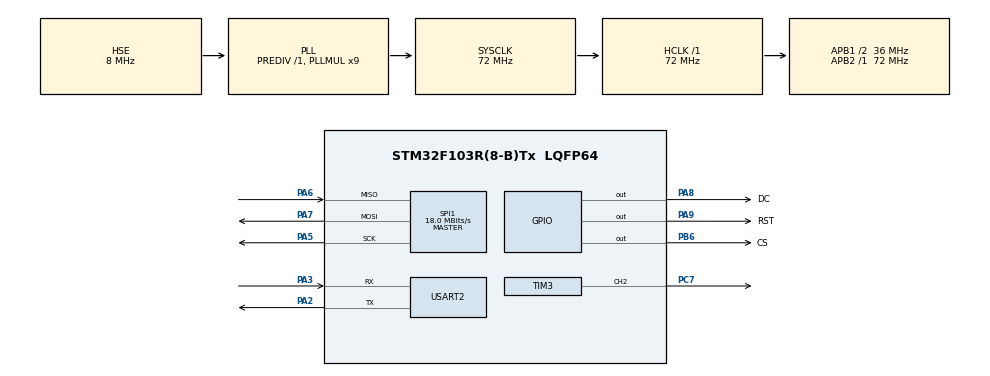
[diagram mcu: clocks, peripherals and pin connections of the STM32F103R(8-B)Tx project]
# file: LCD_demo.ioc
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Mcu.Family=STM32F1
Mcu.Name=STM32F103R(8-B)Tx
Mcu.Package=LQFP64
NVIC.PriorityGroup=NVIC_PRIORITYGROUP_4
PA13.Mode=Serial_Wire
PA13.Signal=SYS_JTMS-SWDIO
PA14.Mode=Serial_Wire
PA14.Signal=SYS_JTCK-SWCLK
PA2.Mode=Asynchronous
PA2.Signal=USART2_TX
PA3.Mode=Asynchronous
PA3.Signal=USART2_RX
PA5.Mode=Full_Duplex_Master
PA5.Signal=SPI1_SCK
PA6.Mode=Full_Duplex_Master
PA6.Signal=SPI1_MISO
PA7.Mode=Full_Duplex_Master
PA7.Signal=SPI1_MOSI
PA8.GPIO_Label=DC
PA8.PinState=GPIO_PIN_SET
PA8.Signal=GPIO_Output
PA9.GPIO_Label=RST
PA9.PinState=GPIO_PIN_SET
PA9.Signal=GPIO_Output
PB6.GPIO_Label=CS
PB6.PinState=GPIO_PIN_SET
PB6.Signal=GPIO_Output
PC7.Signal=S_TIM3_CH2
PD0-OSC_IN.Mode=HSE-External-Oscillator
PD0-OSC_IN.Signal=RCC_OSC_IN
PD1-OSC_OUT.Mode=HSE-External-Oscillator
PD1-OSC_OUT.Signal=RCC_OSC_OUT
ProjectManager.HeapSize=0x200
ProjectManager.StackSize=0x400
ProjectManager.TargetToolchain=STM32CubeIDE
RCC.AHBFreq_Value=72000000
RCC.APB1CLKDivider=RCC_HCLK_DIV2
RCC.APB1Freq_Value=36000000
RCC.APB1TimFreq_Value=72000000
RCC.APB2Freq_Value=72000000
RCC.APB2TimFreq_Value=72000000
RCC.HCLKFreq_Value=72000000
RCC.PLLMUL=RCC_PLL_MUL9
RCC.PLLSourceVirtual=RCC_PLLSOURCE_HSE
RCC.SYSCLKFreq_VALUE=72000000
RCC.SYSCLKSource=RCC_SYSCLKSOURCE_PLLCLK
RCC.USBFreq_Value=72000000
SH.S_TIM3_CH2.0=TIM3_CH2,PWM Generation2 CH2
SPI1.BaudRatePrescaler=SPI_BAUDRATEPRESCALER_4
SPI1.CalculateBaudRate=18.0 MBits/s
SPI1.Direction=SPI_DIRECTION_2LINES
SPI1.Mode=SPI_MODE_MASTER
SPI1.VirtualType=VM_MASTER
TIM3.AutoReloadPreload=TIM_AUTORELOAD_PRELOAD_ENABLE
TIM3.Channel-PWM\ Generation2\ CH2=TIM_CHANNEL_2
TIM3.Period=1000-1
TIM3.Prescaler=300-1
USART2.VirtualMode=VM_ASYNC
board=custom

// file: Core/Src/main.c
/* USER CODE BEGIN Header */
/**
  ******************************************************************************
  * @file           : main.c
  * @brief          : Main program body
  ******************************************************************************
  * @attention
  *
  * Copyright (c) 2024 STMicroelectronics.
  * All rights reserved.
  *
  * This software is licensed under terms that can be found in the LICENSE file
  * in the root directory of this software component.
  * If no LICENSE file comes with this software, it is provided AS-IS.
  *
  ******************************************************************************
  */
/* USER CODE END Header */
#include "main.h"
#include "spi.h"
#include "tim.h"
#include "usart.h"
#include "gpio.h"
#include "LCD_Test.h"

void SystemClock_Config(void);

int main(void)
{

  /* MCU Configuration--------------------------------------------------------*/

  /* Reset of all peripherals, Initializes the Flash interface and the Systick. */
  HAL_Init();

  /* Configure the system clock */
  SystemClock_Config();

  /* Initialize all configured peripherals */
  MX_GPIO_Init();
  MX_SPI1_Init();
  MX_TIM3_Init();
  MX_USART2_UART_Init();
  /* USER CODE BEGIN 2 */
  //LCD_0in96_test();

  //LCD_1in14_test();

  //LCD_1in28_test();

  //LCD_1in3_test();

  //LCD_1in47_test();

  //LCD_1in54_test();

  //LCD_1in69_test();

  //LCD_1in8_test();

  LCD_1in83_test();

  //LCD_1in9_test();

  //LCD_2in_test();

  //LCD_2in4_test();
  /* USER CODE END 2 */

  /* Infinite loop */
  while (1)
  {

  }
}

void SystemClock_Config(void)
{
  RCC_OscInitTypeDef RCC_OscInitStruct = {0};
  RCC_ClkInitTypeDef RCC_ClkInitStruct = {0};

  /** Initializes the RCC Oscillators according to the specified parameters
  * in the RCC_OscInitTypeDef structure.
  */
  RCC_OscInitStruct.OscillatorType = RCC_OSCILLATORTYPE_HSE;
  RCC_OscInitStruct.HSEState = RCC_HSE_ON;
  RCC_OscInitStruct.HSEPredivValue = RCC_HSE_PREDIV_DIV1;
  RCC_OscInitStruct.HSIState = RCC_HSI_ON;
  RCC_OscInitStruct.PLL.PLLState = RCC_PLL_ON;
  RCC_OscInitStruct.PLL.PLLSource = RCC_PLLSOURCE_HSE;
  RCC_OscInitStruct.PLL.PLLMUL = RCC_PLL_MUL9;
  if (HAL_RCC_OscConfig(&RCC_OscInitStruct) != HAL_OK)
  {
    Error_Handler();
  }

  /** Initializes the CPU, AHB and APB buses clocks
  */
  RCC_ClkInitStruct.ClockType = RCC_CLOCKTYPE_HCLK|RCC_CLOCKTYPE_SYSCLK
                              |RCC_CLOCKTYPE_PCLK1|RCC_CLOCKTYPE_PCLK2;
  RCC_ClkInitStruct.SYSCLKSource = RCC_SYSCLKSOURCE_PLLCLK;
  RCC_ClkInitStruct.AHBCLKDivider = RCC_SYSCLK_DIV1;
  RCC_ClkInitStruct.APB1CLKDivider = RCC_HCLK_DIV2;
  RCC_ClkInitStruct.APB2CLKDivider = RCC_HCLK_DIV1;

  if (HAL_RCC_ClockConfig(&RCC_ClkInitStruct, FLASH_LATENCY_2) != HAL_OK)
  {
    Error_Handler();
  }
}

void Error_Handler(void)
{
  __disable_irq();
  while (1)
  {
  }
}
